VERSION ""

NS_ :

BS_ :

BU_: Charger BMS

BO_ 1031 BackEMF: 8 BMS
 SG_ BEMFd : 32|32@1- (1.0,0.0) [-2147483648.0|2147483647.0] "" Charger
 SG_ BEMFq : 0|32@1- (1.0,0.0) [-2147483648.0|2147483647.0] "" Charger
BO_ 57 BIM1BootloaderAddress: 2 BMS
 SG_ BIM1BootloaderAddress : 0|16@1- (1.0,0.0) [-32768.0|32767.0] "" Charger
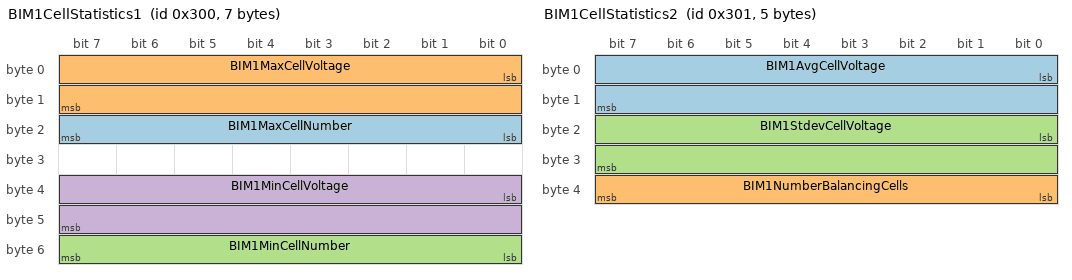
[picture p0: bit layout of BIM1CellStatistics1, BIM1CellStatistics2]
BO_ 768 BIM1CellStatistics1: 7 BMS
 SG_ BIM1MaxCellNumber : 16|8@1- (1.0,0.0) [-128.0|127.0] "" Charger
 SG_ BIM1MaxCellVoltage : 0|16@1- (1.0,0.0) [-32768.0|32767.0] "" Charger
 SG_ BIM1MinCellNumber : 48|8@1- (1.0,0.0) [-128.0|127.0] "" Charger
 SG_ BIM1MinCellVoltage : 32|16@1- (1.0,0.0) [-32768.0|32767.0] "" Charger
BO_ 769 BIM1CellStatistics2: 5 BMS
 SG_ BIM1AvgCellVoltage : 0|16@1- (1.0,0.0) [-32768.0|32767.0] "" Charger
 SG_ BIM1NumberBalancingCells : 32|8@1- (1.0,0.0) [-128.0|127.0] "" Charger
 SG_ BIM1StdevCellVoltage : 16|16@1- (1.0,0.0) [-32768.0|32767.0] "" Charger
BO_ 176 BIM1Command: 8 BMS
 SG_ BIM1CommandCode : 32|32@1- (1.0,0.0) [-2147483648.0|2147483647.0] "" Charger
 SG_ BIM1CommandValue : 0|32@1- (1.0,0.0) [-2147483648.0|2147483647.0] "" Charger
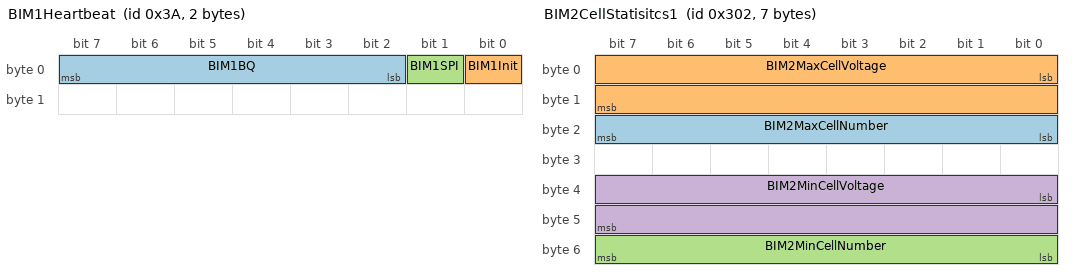
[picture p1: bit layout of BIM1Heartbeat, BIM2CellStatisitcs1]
BO_ 58 BIM1Heartbeat: 2 BMS
 SG_ BIM1BQ : 2|6@1- (1.0,0.0) [-32.0|31.0] "" Charger
 SG_ BIM1Init : 0|1@1- (1.0,0.0) [-1.0|0.0] "" Charger
 SG_ BIM1SPI : 1|1@1- (1.0,0.0) [-1.0|0.0] "" Charger
BO_ 59 BIM2BootloaderAddress: 2 BMS
 SG_ BIM2BootloaderAddres : 0|16@1- (1.0,0.0) [-32768.0|32767.0] "" Charger
BO_ 770 BIM2CellStatisitcs1: 7 BMS
 SG_ BIM2MaxCellNumber : 16|8@1- (1.0,0.0) [-128.0|127.0] "" Charger
 SG_ BIM2MaxCellVoltage : 0|16@1- (1.0,0.0) [-32768.0|32767.0] "" Charger
 SG_ BIM2MinCellNumber : 48|8@1- (1.0,0.0) [-128.0|127.0] "" Charger
 SG_ BIM2MinCellVoltage : 32|16@1- (1.0,0.0) [-32768.0|32767.0] "" Charger
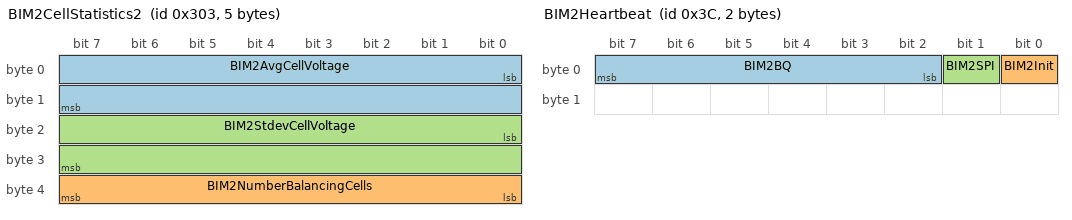
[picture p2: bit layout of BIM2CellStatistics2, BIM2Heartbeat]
BO_ 771 BIM2CellStatistics2: 5 BMS
 SG_ BIM2AvgCellVoltage : 0|16@1- (1.0,0.0) [-32768.0|32767.0] "" Charger
 SG_ BIM2NumberBalancingCells : 32|8@1- (1.0,0.0) [-128.0|127.0] "" Charger
 SG_ BIM2StdevCellVoltage : 16|16@1- (1.0,0.0) [-32768.0|32767.0] "" Charger
BO_ 177 BIM2Command: 8 BMS
 SG_ BIM2CommandCode : 32|32@1- (1.0,0.0) [-2147483648.0|2147483647.0] "" Charger
 SG_ BIM2CommandValue : 0|32@1- (1.0,0.0) [-2147483648.0|2147483647.0] "" Charger
BO_ 60 BIM2Heartbeat: 2 BMS
 SG_ BIM2BQ : 2|6@1- (1.0,0.0) [-32.0|31.0] "" Charger
 SG_ BIM2Init : 0|1@1- (1.0,0.0) [-1.0|0.0] "" Charger
 SG_ BIM2SPI : 1|1@1- (1.0,0.0) [-1.0|0.0] "" Charger
BO_ 61 BIM3BootloaderAddress: 2 BMS
 SG_ BIM3BootloaderAddress : 0|16@1- (1.0,0.0) [-32768.0|32767.0] "" Charger
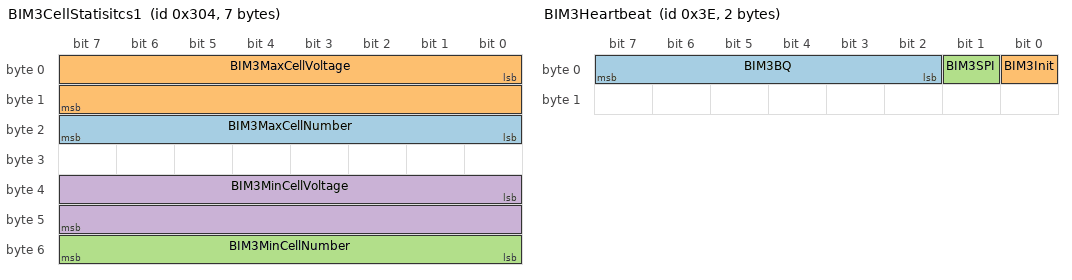
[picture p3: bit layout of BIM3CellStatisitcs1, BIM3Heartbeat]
BO_ 772 BIM3CellStatisitcs1: 7 BMS
 SG_ BIM3MaxCellNumber : 16|8@1- (1.0,0.0) [-128.0|127.0] "" Charger
 SG_ BIM3MaxCellVoltage : 0|16@1- (1.0,0.0) [-32768.0|32767.0] "" Charger
 SG_ BIM3MinCellNumber : 48|8@1- (1.0,0.0) [-128.0|127.0] "" Charger
 SG_ BIM3MinCellVoltage : 32|16@1- (1.0,0.0) [-32768.0|32767.0] "" Charger
BO_ 773 BIM3CellStatistics2: 5 BMS
 SG_ BIM3AvgCellVoltage : 0|16@1- (1.0,0.0) [-32768.0|32767.0] "" Charger
 SG_ BIM3NumberBalancingCells : 32|8@1- (1.0,0.0) [-128.0|127.0] "" Charger
 SG_ BIM3StdevCellVoltage : 16|16@1- (1.0,0.0) [-32768.0|32767.0] "" Charger
BO_ 178 BIM3Command: 8 BMS
 SG_ BIM3CommandCode : 32|32@1- (1.0,0.0) [-2147483648.0|2147483647.0] "" Charger
 SG_ BIM3CommandValue : 0|32@1- (1.0,0.0) [-2147483648.0|2147483647.0] "" Charger
BO_ 62 BIM3Heartbeat: 2 BMS
 SG_ BIM3BQ : 2|6@1- (1.0,0.0) [-32.0|31.0] "" Charger
 SG_ BIM3Init : 0|1@1- (1.0,0.0) [-1.0|0.0] "" Charger
 SG_ BIM3SPI : 1|1@1- (1.0,0.0) [-1.0|0.0] "" Charger
BO_ 63 BIM4BootloaderAddress: 2 BMS
 SG_ BIM4BootloaderAddres : 0|16@1- (1.0,0.0) [-32768.0|32767.0] "" Charger
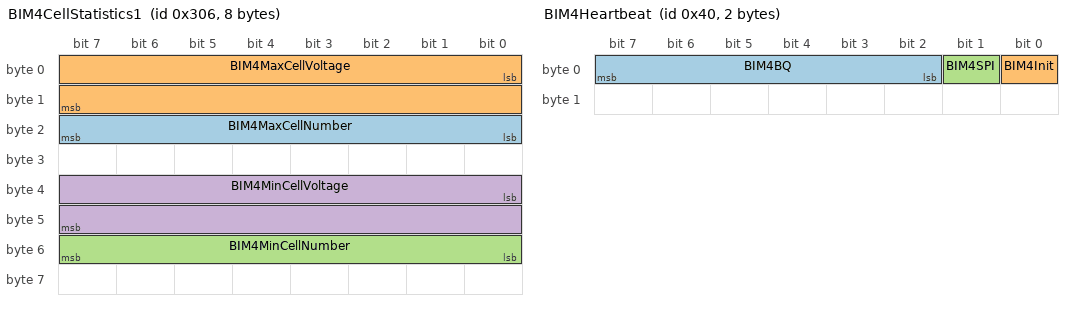
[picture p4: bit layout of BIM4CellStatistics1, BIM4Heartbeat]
BO_ 774 BIM4CellStatistics1: 8 BMS
 SG_ BIM4MaxCellNumber : 16|8@1- (1.0,0.0) [-128.0|127.0] "" Charger
 SG_ BIM4MaxCellVoltage : 0|16@1- (1.0,0.0) [-32768.0|32767.0] "" Charger
 SG_ BIM4MinCellNumber : 48|8@1- (1.0,0.0) [-128.0|127.0] "" Charger
 SG_ BIM4MinCellVoltage : 32|16@1- (1.0,0.0) [-32768.0|32767.0] "" Charger
BO_ 775 BIM4CellStatistics2: 5 BMS
 SG_ BIM4AvgCellVoltage : 0|16@1- (1.0,0.0) [-32768.0|32767.0] "" Charger
 SG_ BIM4NumberBalancingCells : 32|8@1- (1.0,0.0) [-128.0|127.0] "" Charger
 SG_ BIM4StdevCellVoltage : 16|16@1- (1.0,0.0) [-32768.0|32767.0] "" Charger
BO_ 179 BIM4Command: 8 BMS
 SG_ BIM4CommandCode : 32|32@1- (1.0,0.0) [-2147483648.0|2147483647.0] "" Charger
 SG_ BIM4CommandValue : 0|32@1- (1.0,0.0) [-2147483648.0|2147483647.0] "" Charger
BO_ 64 BIM4Heartbeat: 2 BMS
 SG_ BIM4BQ : 2|6@1- (1.0,0.0) [-32.0|31.0] "" Charger
 SG_ BIM4Init : 0|1@1- (1.0,0.0) [-1.0|0.0] "" Charger
 SG_ BIM4SPI : 1|1@1- (1.0,0.0) [-1.0|0.0] "" Charger
BO_ 1026 BusMeasurement: 8 BMS
 SG_ BusCurrent : 32|32@1- (1.0,0.0) [-2147483648.0|2147483647.0] "" Charger
 SG_ BusVoltage : 0|32@1- (1.0,0.0) [-2147483648.0|2147483647.0] "" Charger
BO_ 262 BusVoltage12V: 4 BMS
 SG_ BusVoltage12V : 0|32@1- (1.0,0.0) [-2147483648.0|2147483647.0] "" Charger
BO_ 170 CANcorderHeartbeat: 2 Charger
 SG_ CANcorderHeartbeat : 0|16@1- (1.0,0.0) [-32768.0|32767.0] "" BMS
BO_ 48 CANMirrorBootloaderAddress: 2 Charger
 SG_ CANMirrorBootloaderAddress : 0|16@1- (1.0,0.0) [-32768.0|32767.0] "" BMS
BO_ 50 CANMirrorCommand: 8 Charger
 SG_ CANMirrorCommandCode : 32|32@1- (1.0,0.0) [-2147483648.0|2147483647.0] "" BMS
 SG_ CANMirrorCommandValue : 0|32@1- (1.0,0.0) [-2147483648.0|2147483647.0] "" BMS
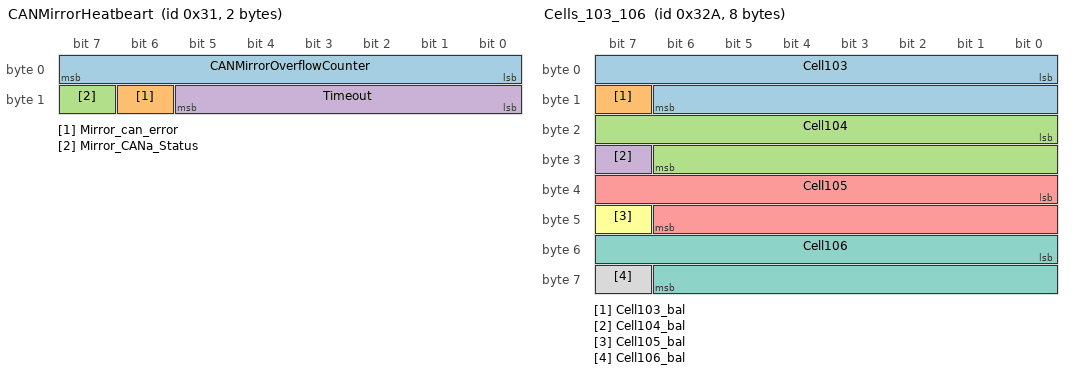
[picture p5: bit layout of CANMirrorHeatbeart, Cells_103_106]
BO_ 49 CANMirrorHeatbeart: 2 Charger
 SG_ CANMirrorOverflowCounter : 0|8@1- (1.0,0.0) [-128.0|127.0] "" BMS
 SG_ Mirror_can_error : 14|1@1- (1.0,0.0) [-1.0|0.0] "" BMS
 SG_ Mirror_CANa_Status : 15|1@1- (1.0,0.0) [-1.0|0.0] "" BMS
 SG_ Timeout : 8|6@1- (1.0,0.0) [-32.0|31.0] "" BMS
BO_ 810 Cells_103_106: 8 Charger
 SG_ Cell103 : 0|15@1- (1.0,0.0) [-16384.0|16383.0] "" BMS
 SG_ Cell103_bal : 15|1@1- (1.0,0.0) [-1.0|0.0] "" BMS
 SG_ Cell104 : 16|15@1- (1.0,0.0) [-16384.0|16383.0] "" BMS
 SG_ Cell104_bal : 31|1@1- (1.0,0.0) [-1.0|0.0] "" BMS
 SG_ Cell105 : 32|15@1- (1.0,0.0) [-16384.0|16383.0] "" BMS
 SG_ Cell105_bal : 47|1@1- (1.0,0.0) [-1.0|0.0] "" BMS
 SG_ Cell106 : 48|15@1- (1.0,0.0) [-16384.0|16383.0] "" BMS
 SG_ Cell106_bal : 63|1@1- (1.0,0.0) [-1.0|0.0] "" BMS
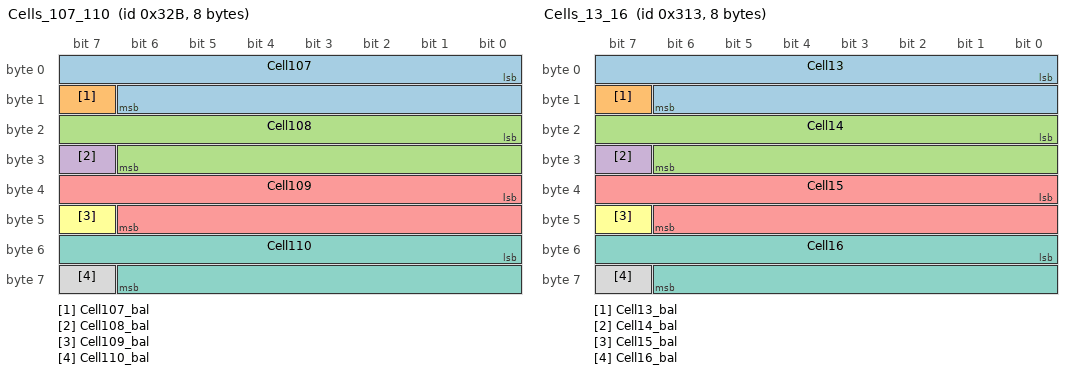
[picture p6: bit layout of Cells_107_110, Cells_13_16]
BO_ 811 Cells_107_110: 8 Charger
 SG_ Cell107 : 0|15@1- (1.0,0.0) [-16384.0|16383.0] "" BMS
 SG_ Cell107_bal : 15|1@1- (1.0,0.0) [-1.0|0.0] "" BMS
 SG_ Cell108 : 16|15@1- (1.0,0.0) [-16384.0|16383.0] "" BMS
 SG_ Cell108_bal : 31|1@1- (1.0,0.0) [-1.0|0.0] "" BMS
 SG_ Cell109 : 32|15@1- (1.0,0.0) [-16384.0|16383.0] "" BMS
 SG_ Cell109_bal : 47|1@1- (1.0,0.0) [-1.0|0.0] "" BMS
 SG_ Cell110 : 48|15@1- (1.0,0.0) [-16384.0|16383.0] "" BMS
 SG_ Cell110_bal : 63|1@1- (1.0,0.0) [-1.0|0.0] "" BMS
BO_ 787 Cells_13_16: 8 Charger
 SG_ Cell13 : 0|15@1- (1.0,0.0) [-16384.0|16383.0] "" BMS
 SG_ Cell13_bal : 15|1@1- (1.0,0.0) [-1.0|0.0] "" BMS
 SG_ Cell14 : 16|15@1- (1.0,0.0) [-16384.0|16383.0] "" BMS
 SG_ Cell14_bal : 31|1@1- (1.0,0.0) [-1.0|0.0] "" BMS
 SG_ Cell15 : 32|15@1- (1.0,0.0) [-16384.0|16383.0] "" BMS
 SG_ Cell15_bal : 47|1@1- (1.0,0.0) [-1.0|0.0] "" BMS
 SG_ Cell16 : 48|15@1- (1.0,0.0) [-16384.0|16383.0] "" BMS
 SG_ Cell16_bal : 63|1@1- (1.0,0.0) [-1.0|0.0] "" BMS
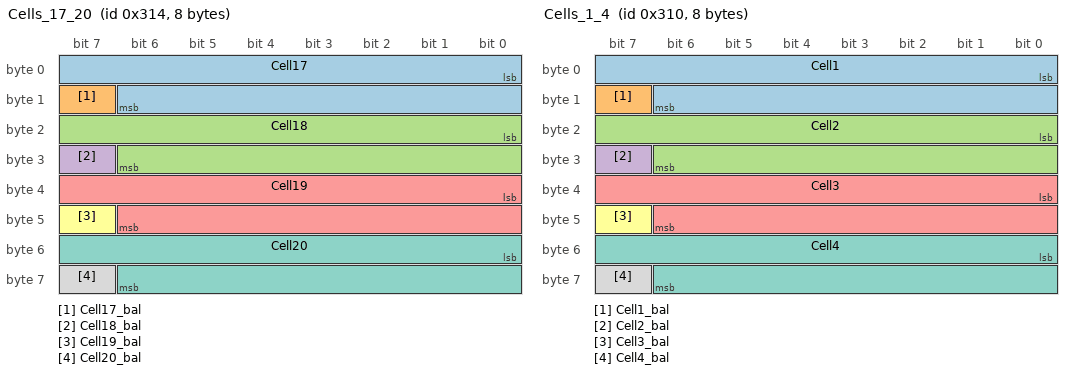
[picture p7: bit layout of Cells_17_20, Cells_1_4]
BO_ 788 Cells_17_20: 8 Charger
 SG_ Cell17 : 0|15@1- (1.0,0.0) [-16384.0|16383.0] "" BMS
 SG_ Cell17_bal : 15|1@1- (1.0,0.0) [-1.0|0.0] "" BMS
 SG_ Cell18 : 16|15@1- (1.0,0.0) [-16384.0|16383.0] "" BMS
 SG_ Cell18_bal : 31|1@1- (1.0,0.0) [-1.0|0.0] "" BMS
 SG_ Cell19 : 32|15@1- (1.0,0.0) [-16384.0|16383.0] "" BMS
 SG_ Cell19_bal : 47|1@1- (1.0,0.0) [-1.0|0.0] "" BMS
 SG_ Cell20 : 48|15@1- (1.0,0.0) [-16384.0|16383.0] "" BMS
 SG_ Cell20_bal : 63|1@1- (1.0,0.0) [-1.0|0.0] "" BMS
BO_ 784 Cells_1_4: 8 Charger
 SG_ Cell1 : 0|15@1- (1.0,0.0) [-16384.0|16383.0] "" BMS
 SG_ Cell1_bal : 15|1@1- (1.0,0.0) [-1.0|0.0] "" BMS
 SG_ Cell2 : 16|15@1- (1.0,0.0) [-16384.0|16383.0] "" BMS
 SG_ Cell2_bal : 31|1@1- (1.0,0.0) [-1.0|0.0] "" BMS
 SG_ Cell3 : 32|15@1- (1.0,0.0) [-16384.0|16383.0] "" BMS
 SG_ Cell3_bal : 47|1@1- (1.0,0.0) [-1.0|0.0] "" BMS
 SG_ Cell4 : 48|15@1- (1.0,0.0) [-16384.0|16383.0] "" BMS
 SG_ Cell4_bal : 63|1@1- (1.0,0.0) [-1.0|0.0] "" BMS
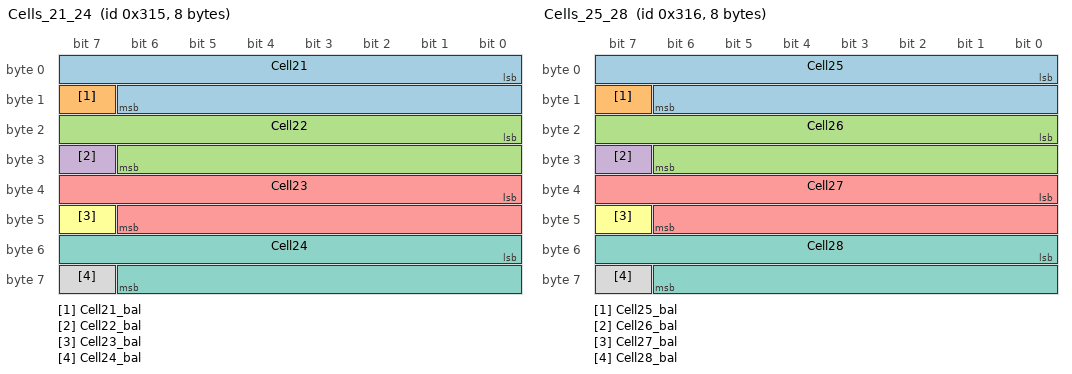
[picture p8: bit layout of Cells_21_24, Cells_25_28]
BO_ 789 Cells_21_24: 8 Charger
 SG_ Cell21 : 0|15@1- (1.0,0.0) [-16384.0|16383.0] "" BMS
 SG_ Cell21_bal : 15|1@1- (1.0,0.0) [-1.0|0.0] "" BMS
 SG_ Cell22 : 16|15@1- (1.0,0.0) [-16384.0|16383.0] "" BMS
 SG_ Cell22_bal : 31|1@1- (1.0,0.0) [-1.0|0.0] "" BMS
 SG_ Cell23 : 32|15@1- (1.0,0.0) [-16384.0|16383.0] "" BMS
 SG_ Cell23_bal : 47|1@1- (1.0,0.0) [-1.0|0.0] "" BMS
 SG_ Cell24 : 48|15@1- (1.0,0.0) [-16384.0|16383.0] "" BMS
 SG_ Cell24_bal : 63|1@1- (1.0,0.0) [-1.0|0.0] "" BMS
BO_ 790 Cells_25_28: 8 Charger
 SG_ Cell25 : 0|15@1- (1.0,0.0) [-16384.0|16383.0] "" BMS
 SG_ Cell25_bal : 15|1@1- (1.0,0.0) [-1.0|0.0] "" BMS
 SG_ Cell26 : 16|15@1- (1.0,0.0) [-16384.0|16383.0] "" BMS
 SG_ Cell26_bal : 31|1@1- (1.0,0.0) [-1.0|0.0] "" BMS
 SG_ Cell27 : 32|15@1- (1.0,0.0) [-16384.0|16383.0] "" BMS
 SG_ Cell27_bal : 47|1@1- (1.0,0.0) [-1.0|0.0] "" BMS
 SG_ Cell28 : 48|15@1- (1.0,0.0) [-16384.0|16383.0] "" BMS
 SG_ Cell28_bal : 63|1@1- (1.0,0.0) [-1.0|0.0] "" BMS
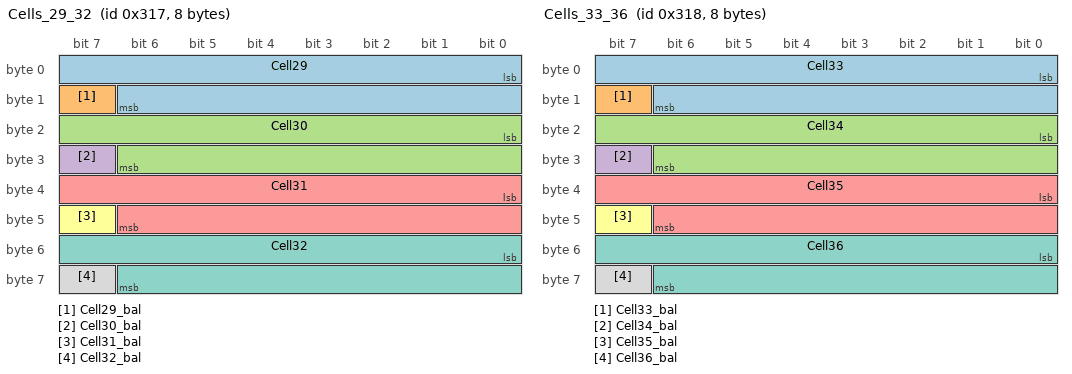
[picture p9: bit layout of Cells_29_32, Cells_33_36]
BO_ 791 Cells_29_32: 8 Charger
 SG_ Cell29 : 0|15@1- (1.0,0.0) [-16384.0|16383.0] "" BMS
 SG_ Cell29_bal : 15|1@1- (1.0,0.0) [-1.0|0.0] "" BMS
 SG_ Cell30 : 16|15@1- (1.0,0.0) [-16384.0|16383.0] "" BMS
 SG_ Cell30_bal : 31|1@1- (1.0,0.0) [-1.0|0.0] "" BMS
 SG_ Cell31 : 32|15@1- (1.0,0.0) [-16384.0|16383.0] "" BMS
 SG_ Cell31_bal : 47|1@1- (1.0,0.0) [-1.0|0.0] "" BMS
 SG_ Cell32 : 48|15@1- (1.0,0.0) [-16384.0|16383.0] "" BMS
 SG_ Cell32_bal : 63|1@1- (1.0,0.0) [-1.0|0.0] "" BMS
BO_ 792 Cells_33_36: 8 Charger
 SG_ Cell33 : 0|15@1- (1.0,0.0) [-16384.0|16383.0] "" BMS
 SG_ Cell33_bal : 15|1@1- (1.0,0.0) [-1.0|0.0] "" BMS
 SG_ Cell34 : 16|15@1- (1.0,0.0) [-16384.0|16383.0] "" BMS
 SG_ Cell34_bal : 31|1@1- (1.0,0.0) [-1.0|0.0] "" BMS
 SG_ Cell35 : 32|15@1- (1.0,0.0) [-16384.0|16383.0] "" BMS
 SG_ Cell35_bal : 47|1@1- (1.0,0.0) [-1.0|0.0] "" BMS
 SG_ Cell36 : 48|15@1- (1.0,0.0) [-16384.0|16383.0] "" BMS
 SG_ Cell36_bal : 63|1@1- (1.0,0.0) [-1.0|0.0] "" BMS
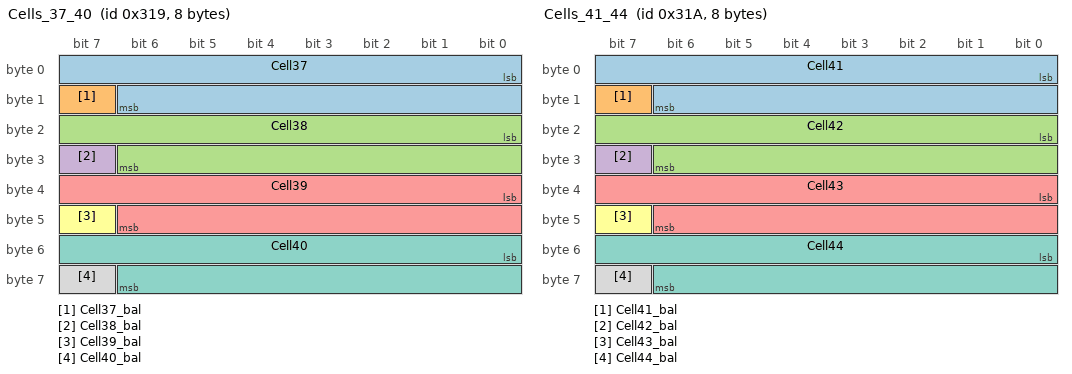
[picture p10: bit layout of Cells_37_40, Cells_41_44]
BO_ 793 Cells_37_40: 8 Charger
 SG_ Cell37 : 0|15@1- (1.0,0.0) [-16384.0|16383.0] "" BMS
 SG_ Cell37_bal : 15|1@1- (1.0,0.0) [-1.0|0.0] "" BMS
 SG_ Cell38 : 16|15@1- (1.0,0.0) [-16384.0|16383.0] "" BMS
 SG_ Cell38_bal : 31|1@1- (1.0,0.0) [-1.0|0.0] "" BMS
 SG_ Cell39 : 32|15@1- (1.0,0.0) [-16384.0|16383.0] "" BMS
 SG_ Cell39_bal : 47|1@1- (1.0,0.0) [-1.0|0.0] "" BMS
 SG_ Cell40 : 48|15@1- (1.0,0.0) [-16384.0|16383.0] "" BMS
 SG_ Cell40_bal : 63|1@1- (1.0,0.0) [-1.0|0.0] "" BMS
BO_ 794 Cells_41_44: 8 Charger
 SG_ Cell41 : 0|15@1- (1.0,0.0) [-16384.0|16383.0] "" BMS
 SG_ Cell41_bal : 15|1@1- (1.0,0.0) [-1.0|0.0] "" BMS
 SG_ Cell42 : 16|15@1- (1.0,0.0) [-16384.0|16383.0] "" BMS
 SG_ Cell42_bal : 31|1@1- (1.0,0.0) [-1.0|0.0] "" BMS
 SG_ Cell43 : 32|15@1- (1.0,0.0) [-16384.0|16383.0] "" BMS
 SG_ Cell43_bal : 47|1@1- (1.0,0.0) [-1.0|0.0] "" BMS
 SG_ Cell44 : 48|15@1- (1.0,0.0) [-16384.0|16383.0] "" BMS
 SG_ Cell44_bal : 63|1@1- (1.0,0.0) [-1.0|0.0] "" BMS
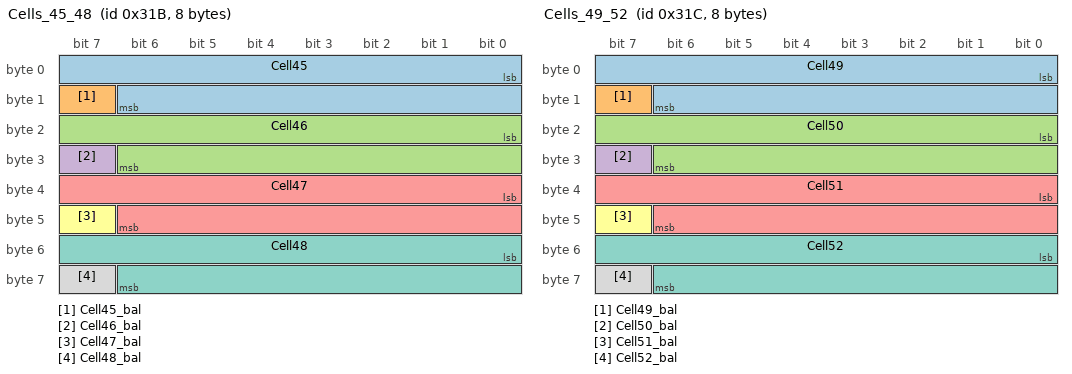
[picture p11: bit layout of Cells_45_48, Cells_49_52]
BO_ 795 Cells_45_48: 8 Charger
 SG_ Cell45 : 0|15@1- (1.0,0.0) [-16384.0|16383.0] "" BMS
 SG_ Cell45_bal : 15|1@1- (1.0,0.0) [-1.0|0.0] "" BMS
 SG_ Cell46 : 16|15@1- (1.0,0.0) [-16384.0|16383.0] "" BMS
 SG_ Cell46_bal : 31|1@1- (1.0,0.0) [-1.0|0.0] "" BMS
 SG_ Cell47 : 32|15@1- (1.0,0.0) [-16384.0|16383.0] "" BMS
 SG_ Cell47_bal : 47|1@1- (1.0,0.0) [-1.0|0.0] "" BMS
 SG_ Cell48 : 48|15@1- (1.0,0.0) [-16384.0|16383.0] "" BMS
 SG_ Cell48_bal : 63|1@1- (1.0,0.0) [-1.0|0.0] "" BMS
BO_ 796 Cells_49_52: 8 Charger
 SG_ Cell49 : 0|15@1- (1.0,0.0) [-16384.0|16383.0] "" BMS
 SG_ Cell49_bal : 15|1@1- (1.0,0.0) [-1.0|0.0] "" BMS
 SG_ Cell50 : 16|15@1- (1.0,0.0) [-16384.0|16383.0] "" BMS
 SG_ Cell50_bal : 31|1@1- (1.0,0.0) [-1.0|0.0] "" BMS
 SG_ Cell51 : 32|15@1- (1.0,0.0) [-16384.0|16383.0] "" BMS
 SG_ Cell51_bal : 47|1@1- (1.0,0.0) [-1.0|0.0] "" BMS
 SG_ Cell52 : 48|15@1- (1.0,0.0) [-16384.0|16383.0] "" BMS
 SG_ Cell52_bal : 63|1@1- (1.0,0.0) [-1.0|0.0] "" BMS
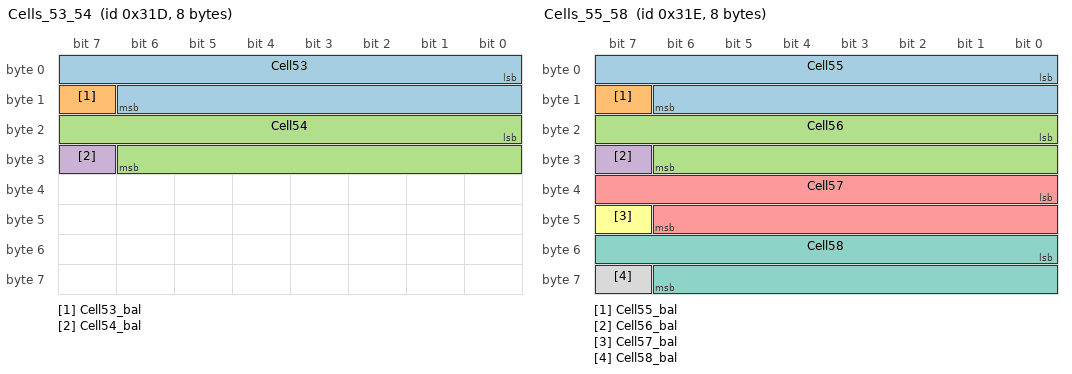
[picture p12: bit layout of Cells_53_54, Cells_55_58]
BO_ 797 Cells_53_54: 8 Charger
 SG_ Cell53 : 0|15@1- (1.0,0.0) [-16384.0|16383.0] "" BMS
 SG_ Cell53_bal : 15|1@1- (1.0,0.0) [-1.0|0.0] "" BMS
 SG_ Cell54 : 16|15@1- (1.0,0.0) [-16384.0|16383.0] "" BMS
 SG_ Cell54_bal : 31|1@1- (1.0,0.0) [-1.0|0.0] "" BMS
BO_ 798 Cells_55_58: 8 Charger
 SG_ Cell55 : 0|15@1- (1.0,0.0) [-16384.0|16383.0] "" BMS
 SG_ Cell55_bal : 15|1@1- (1.0,0.0) [-1.0|0.0] "" BMS
 SG_ Cell56 : 16|15@1- (1.0,0.0) [-16384.0|16383.0] "" BMS
 SG_ Cell56_bal : 31|1@1- (1.0,0.0) [-1.0|0.0] "" BMS
 SG_ Cell57 : 32|15@1- (1.0,0.0) [-16384.0|16383.0] "" BMS
 SG_ Cell57_bal : 47|1@1- (1.0,0.0) [-1.0|0.0] "" BMS
 SG_ Cell58 : 48|15@1- (1.0,0.0) [-16384.0|16383.0] "" BMS
 SG_ Cell58_bal : 63|1@1- (1.0,0.0) [-1.0|0.0] "" BMS
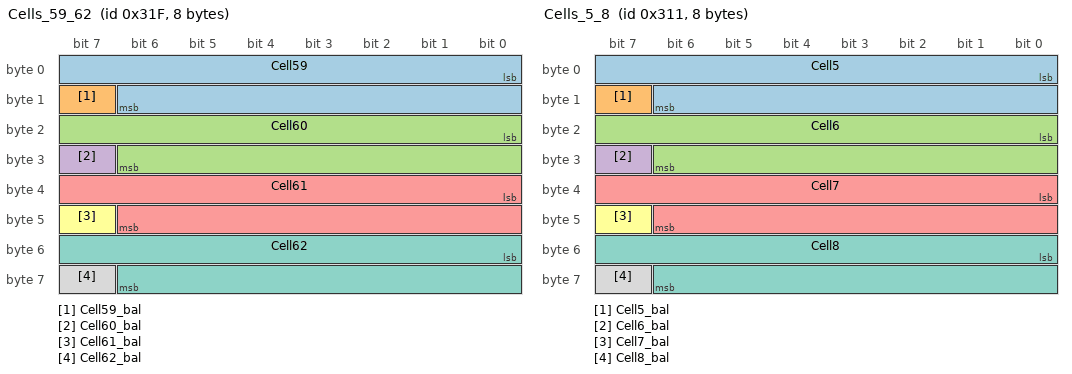
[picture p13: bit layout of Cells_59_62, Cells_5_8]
BO_ 799 Cells_59_62: 8 Charger
 SG_ Cell59 : 0|15@1- (1.0,0.0) [-16384.0|16383.0] "" BMS
 SG_ Cell59_bal : 15|1@1- (1.0,0.0) [-1.0|0.0] "" BMS
 SG_ Cell60 : 16|15@1- (1.0,0.0) [-16384.0|16383.0] "" BMS
 SG_ Cell60_bal : 31|1@1- (1.0,0.0) [-1.0|0.0] "" BMS
 SG_ Cell61 : 32|15@1- (1.0,0.0) [-16384.0|16383.0] "" BMS
 SG_ Cell61_bal : 47|1@1- (1.0,0.0) [-1.0|0.0] "" BMS
 SG_ Cell62 : 48|15@1- (1.0,0.0) [-16384.0|16383.0] "" BMS
 SG_ Cell62_bal : 63|1@1- (1.0,0.0) [-1.0|0.0] "" BMS
BO_ 785 Cells_5_8: 8 Charger
 SG_ Cell5 : 0|15@1- (1.0,0.0) [-16384.0|16383.0] "" BMS
 SG_ Cell5_bal : 15|1@1- (1.0,0.0) [-1.0|0.0] "" BMS
 SG_ Cell6 : 16|15@1- (1.0,0.0) [-16384.0|16383.0] "" BMS
 SG_ Cell6_bal : 31|1@1- (1.0,0.0) [-1.0|0.0] "" BMS
 SG_ Cell7 : 32|15@1- (1.0,0.0) [-16384.0|16383.0] "" BMS
 SG_ Cell7_bal : 47|1@1- (1.0,0.0) [-1.0|0.0] "" BMS
 SG_ Cell8 : 48|15@1- (1.0,0.0) [-16384.0|16383.0] "" BMS
 SG_ Cell8_bal : 63|1@1- (1.0,0.0) [-1.0|0.0] "" BMS
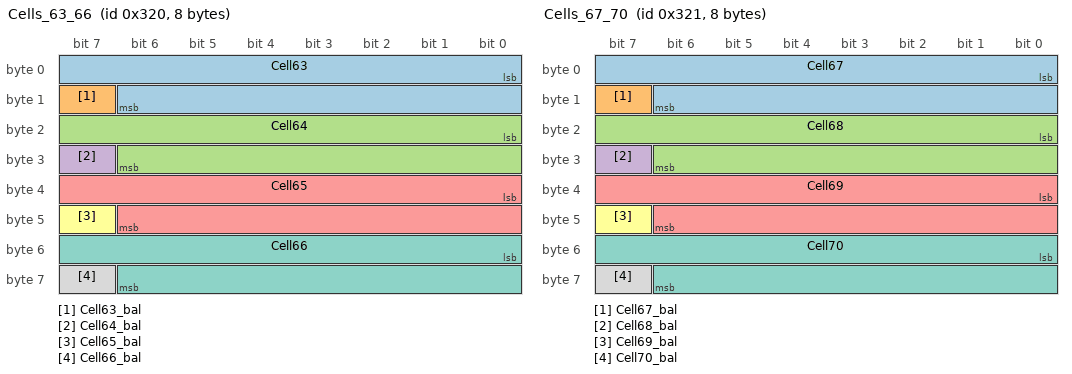
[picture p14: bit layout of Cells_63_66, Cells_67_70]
BO_ 800 Cells_63_66: 8 Charger
 SG_ Cell63 : 0|15@1- (1.0,0.0) [-16384.0|16383.0] "" BMS
 SG_ Cell63_bal : 15|1@1- (1.0,0.0) [-1.0|0.0] "" BMS
 SG_ Cell64 : 16|15@1- (1.0,0.0) [-16384.0|16383.0] "" BMS
 SG_ Cell64_bal : 31|1@1- (1.0,0.0) [-1.0|0.0] "" BMS
 SG_ Cell65 : 32|15@1- (1.0,0.0) [-16384.0|16383.0] "" BMS
 SG_ Cell65_bal : 47|1@1- (1.0,0.0) [-1.0|0.0] "" BMS
 SG_ Cell66 : 48|15@1- (1.0,0.0) [-16384.0|16383.0] "" BMS
 SG_ Cell66_bal : 63|1@1- (1.0,0.0) [-1.0|0.0] "" BMS
BO_ 801 Cells_67_70: 8 Charger
 SG_ Cell67 : 0|15@1- (1.0,0.0) [-16384.0|16383.0] "" BMS
 SG_ Cell67_bal : 15|1@1- (1.0,0.0) [-1.0|0.0] "" BMS
 SG_ Cell68 : 16|15@1- (1.0,0.0) [-16384.0|16383.0] "" BMS
 SG_ Cell68_bal : 31|1@1- (1.0,0.0) [-1.0|0.0] "" BMS
 SG_ Cell69 : 32|15@1- (1.0,0.0) [-16384.0|16383.0] "" BMS
 SG_ Cell69_bal : 47|1@1- (1.0,0.0) [-1.0|0.0] "" BMS
 SG_ Cell70 : 48|15@1- (1.0,0.0) [-16384.0|16383.0] "" BMS
 SG_ Cell70_bal : 63|1@1- (1.0,0.0) [-1.0|0.0] "" BMS
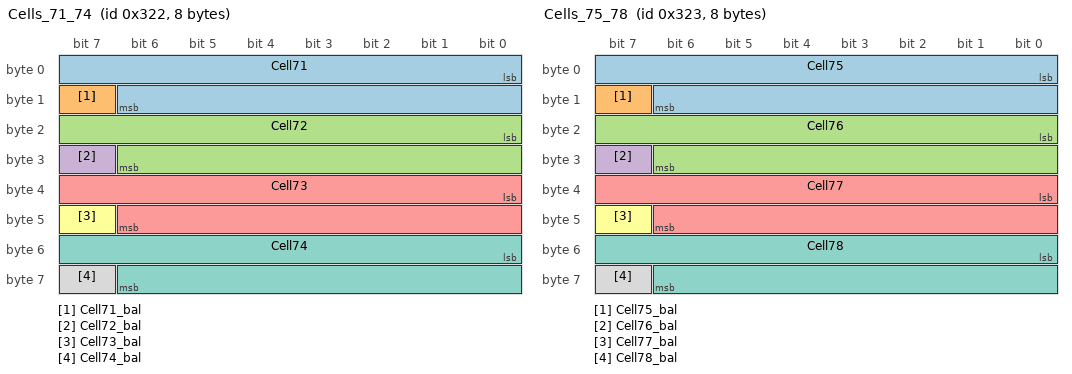
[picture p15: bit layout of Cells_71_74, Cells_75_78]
BO_ 802 Cells_71_74: 8 Charger
 SG_ Cell71 : 0|15@1- (1.0,0.0) [-16384.0|16383.0] "" BMS
 SG_ Cell71_bal : 15|1@1- (1.0,0.0) [-1.0|0.0] "" BMS
 SG_ Cell72 : 16|15@1- (1.0,0.0) [-16384.0|16383.0] "" BMS
 SG_ Cell72_bal : 31|1@1- (1.0,0.0) [-1.0|0.0] "" BMS
 SG_ Cell73 : 32|15@1- (1.0,0.0) [-16384.0|16383.0] "" BMS
 SG_ Cell73_bal : 47|1@1- (1.0,0.0) [-1.0|0.0] "" BMS
 SG_ Cell74 : 48|15@1- (1.0,0.0) [-16384.0|16383.0] "" BMS
 SG_ Cell74_bal : 63|1@1- (1.0,0.0) [-1.0|0.0] "" BMS
BO_ 803 Cells_75_78: 8 Charger
 SG_ Cell75 : 0|15@1- (1.0,0.0) [-16384.0|16383.0] "" BMS
 SG_ Cell75_bal : 15|1@1- (1.0,0.0) [-1.0|0.0] "" BMS
 SG_ Cell76 : 16|15@1- (1.0,0.0) [-16384.0|16383.0] "" BMS
 SG_ Cell76_bal : 31|1@1- (1.0,0.0) [-1.0|0.0] "" BMS
 SG_ Cell77 : 32|15@1- (1.0,0.0) [-16384.0|16383.0] "" BMS
 SG_ Cell77_bal : 47|1@1- (1.0,0.0) [-1.0|0.0] "" BMS
 SG_ Cell78 : 48|15@1- (1.0,0.0) [-16384.0|16383.0] "" BMS
 SG_ Cell78_bal : 63|1@1- (1.0,0.0) [-1.0|0.0] "" BMS
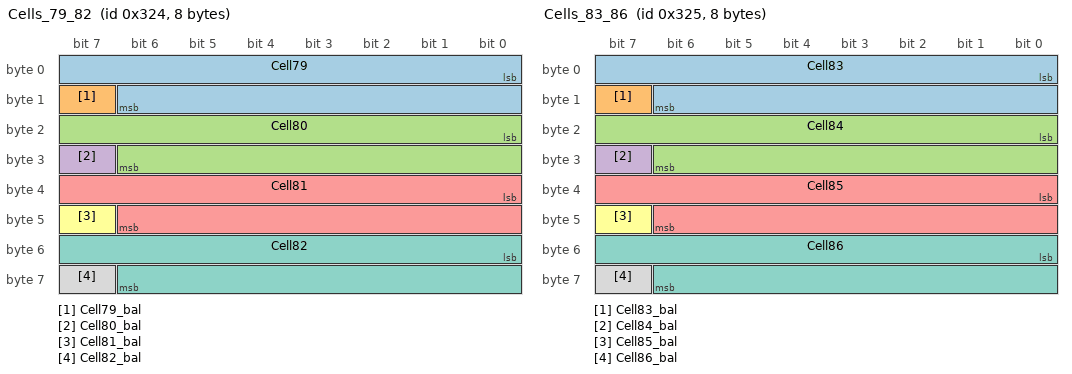
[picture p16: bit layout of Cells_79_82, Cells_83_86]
BO_ 804 Cells_79_82: 8 Charger
 SG_ Cell79 : 0|15@1- (1.0,0.0) [-16384.0|16383.0] "" BMS
 SG_ Cell79_bal : 15|1@1- (1.0,0.0) [-1.0|0.0] "" BMS
 SG_ Cell80 : 16|15@1- (1.0,0.0) [-16384.0|16383.0] "" BMS
 SG_ Cell80_bal : 31|1@1- (1.0,0.0) [-1.0|0.0] "" BMS
 SG_ Cell81 : 32|15@1- (1.0,0.0) [-16384.0|16383.0] "" BMS
 SG_ Cell81_bal : 47|1@1- (1.0,0.0) [-1.0|0.0] "" BMS
 SG_ Cell82 : 48|15@1- (1.0,0.0) [-16384.0|16383.0] "" BMS
 SG_ Cell82_bal : 63|1@1- (1.0,0.0) [-1.0|0.0] "" BMS
BO_ 805 Cells_83_86: 8 Charger
 SG_ Cell83 : 0|15@1- (1.0,0.0) [-16384.0|16383.0] "" BMS
 SG_ Cell83_bal : 15|1@1- (1.0,0.0) [-1.0|0.0] "" BMS
 SG_ Cell84 : 16|15@1- (1.0,0.0) [-16384.0|16383.0] "" BMS
 SG_ Cell84_bal : 31|1@1- (1.0,0.0) [-1.0|0.0] "" BMS
 SG_ Cell85 : 32|15@1- (1.0,0.0) [-16384.0|16383.0] "" BMS
 SG_ Cell85_bal : 47|1@1- (1.0,0.0) [-1.0|0.0] "" BMS
 SG_ Cell86 : 48|15@1- (1.0,0.0) [-16384.0|16383.0] "" BMS
 SG_ Cell86_bal : 63|1@1- (1.0,0.0) [-1.0|0.0] "" BMS
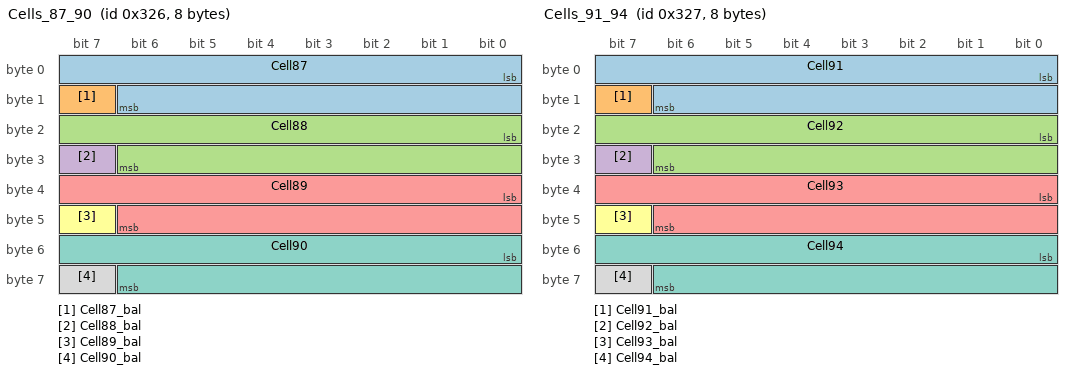
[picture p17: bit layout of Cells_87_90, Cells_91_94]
BO_ 806 Cells_87_90: 8 Charger
 SG_ Cell87 : 0|15@1- (1.0,0.0) [-16384.0|16383.0] "" BMS
 SG_ Cell87_bal : 15|1@1- (1.0,0.0) [-1.0|0.0] "" BMS
 SG_ Cell88 : 16|15@1- (1.0,0.0) [-16384.0|16383.0] "" BMS
 SG_ Cell88_bal : 31|1@1- (1.0,0.0) [-1.0|0.0] "" BMS
 SG_ Cell89 : 32|15@1- (1.0,0.0) [-16384.0|16383.0] "" BMS
 SG_ Cell89_bal : 47|1@1- (1.0,0.0) [-1.0|0.0] "" BMS
 SG_ Cell90 : 48|15@1- (1.0,0.0) [-16384.0|16383.0] "" BMS
 SG_ Cell90_bal : 63|1@1- (1.0,0.0) [-1.0|0.0] "" BMS
BO_ 807 Cells_91_94: 8 Charger
 SG_ Cell91 : 0|15@1- (1.0,0.0) [-16384.0|16383.0] "" BMS
 SG_ Cell91_bal : 15|1@1- (1.0,0.0) [-1.0|0.0] "" BMS
 SG_ Cell92 : 16|15@1- (1.0,0.0) [-16384.0|16383.0] "" BMS
 SG_ Cell92_bal : 31|1@1- (1.0,0.0) [-1.0|0.0] "" BMS
 SG_ Cell93 : 32|15@1- (1.0,0.0) [-16384.0|16383.0] "" BMS
 SG_ Cell93_bal : 47|1@1- (1.0,0.0) [-1.0|0.0] "" BMS
 SG_ Cell94 : 48|15@1- (1.0,0.0) [-16384.0|16383.0] "" BMS
 SG_ Cell94_bal : 63|1@1- (1.0,0.0) [-1.0|0.0] "" BMS
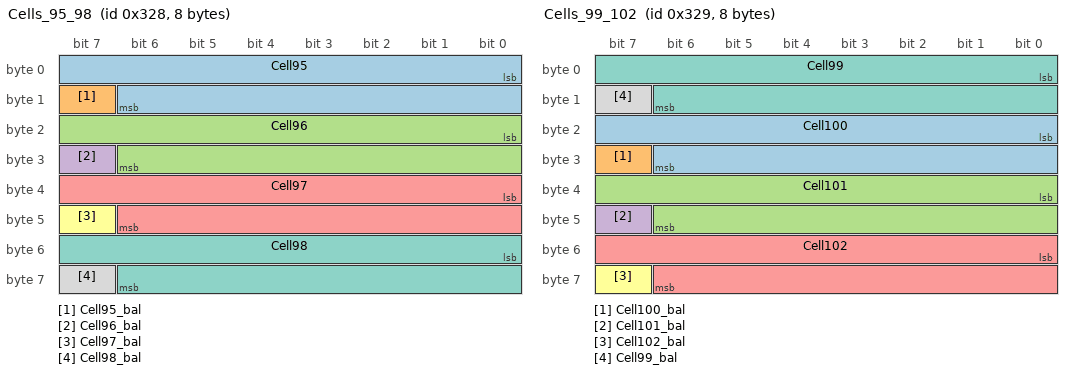
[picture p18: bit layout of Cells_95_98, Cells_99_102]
BO_ 808 Cells_95_98: 8 Charger
 SG_ Cell95 : 0|15@1- (1.0,0.0) [-16384.0|16383.0] "" BMS
 SG_ Cell95_bal : 15|1@1- (1.0,0.0) [-1.0|0.0] "" BMS
 SG_ Cell96 : 16|15@1- (1.0,0.0) [-16384.0|16383.0] "" BMS
 SG_ Cell96_bal : 31|1@1- (1.0,0.0) [-1.0|0.0] "" BMS
 SG_ Cell97 : 32|15@1- (1.0,0.0) [-16384.0|16383.0] "" BMS
 SG_ Cell97_bal : 47|1@1- (1.0,0.0) [-1.0|0.0] "" BMS
 SG_ Cell98 : 48|15@1- (1.0,0.0) [-16384.0|16383.0] "" BMS
 SG_ Cell98_bal : 63|1@1- (1.0,0.0) [-1.0|0.0] "" BMS
BO_ 809 Cells_99_102: 8 Charger
 SG_ Cell100 : 16|15@1- (1.0,0.0) [-16384.0|16383.0] "" BMS
 SG_ Cell100_bal : 31|1@1- (1.0,0.0) [-1.0|0.0] "" BMS
 SG_ Cell101 : 32|15@1- (1.0,0.0) [-16384.0|16383.0] "" BMS
 SG_ Cell101_bal : 47|1@1- (1.0,0.0) [-1.0|0.0] "" BMS
 SG_ Cell102 : 48|15@1- (1.0,0.0) [-16384.0|16383.0] "" BMS
 SG_ Cell102_bal : 63|1@1- (1.0,0.0) [-1.0|0.0] "" BMS
 SG_ Cell99 : 0|15@1- (1.0,0.0) [-16384.0|16383.0] "" BMS
 SG_ Cell99_bal : 15|1@1- (1.0,0.0) [-1.0|0.0] "" BMS
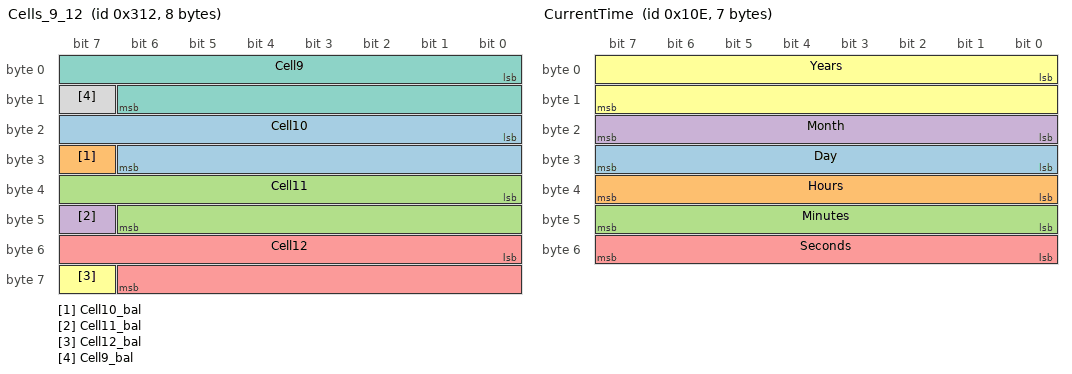
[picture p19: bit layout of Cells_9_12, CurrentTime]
BO_ 786 Cells_9_12: 8 Charger
 SG_ Cell10 : 16|15@1- (1.0,0.0) [-16384.0|16383.0] "" BMS
 SG_ Cell10_bal : 31|1@1- (1.0,0.0) [-1.0|0.0] "" BMS
 SG_ Cell11 : 32|15@1- (1.0,0.0) [-16384.0|16383.0] "" BMS
 SG_ Cell11_bal : 47|1@1- (1.0,0.0) [-1.0|0.0] "" BMS
 SG_ Cell12 : 48|15@1- (1.0,0.0) [-16384.0|16383.0] "" BMS
 SG_ Cell12_bal : 63|1@1- (1.0,0.0) [-1.0|0.0] "" BMS
 SG_ Cell9 : 0|15@1- (1.0,0.0) [-16384.0|16383.0] "" BMS
 SG_ Cell9_bal : 15|1@1- (1.0,0.0) [-1.0|0.0] "" BMS
BO_ 270 CurrentTime: 7 Charger
 SG_ Day : 24|8@1- (1.0,0.0) [-128.0|127.0] "" BMS
 SG_ Hours : 32|8@1- (1.0,0.0) [-128.0|127.0] "" BMS
 SG_ Minutes : 40|8@1- (1.0,0.0) [-128.0|127.0] "" BMS
 SG_ Month : 16|8@1- (1.0,0.0) [-128.0|127.0] "" BMS
 SG_ Seconds : 48|8@1- (1.0,0.0) [-128.0|127.0] "" BMS
 SG_ Years : 0|16@1- (1.0,0.0) [-32768.0|32767.0] "" BMS
BA_DEF_ BO_ "GenMsgSendType" ENUM "cyclic";
BA_DEF_ SG_ "GenSigSendType" ENUM "cyclic";
BA_DEF_ BO_ "GenMsgCycleTime" INT 0 5000;
BA_ "GenMsgSendType" BO_ 1031 0;
BA_ "GenMsgCycleTime" BO_ 1031 500;
BA_ "GenSigSendType" SG_ 1031 BEMFd 0;
BA_ "GenSigSendType" SG_ 1031 BEMFq 0;
BA_ "GenMsgSendType" BO_ 57 0;
BA_ "GenMsgCycleTime" BO_ 57 5000;
BA_ "GenSigSendType" SG_ 57 BIM1BootloaderAddress 0;
BA_ "GenMsgSendType" BO_ 768 0;
BA_ "GenMsgCycleTime" BO_ 768 200;
BA_ "GenSigSendType" SG_ 768 BIM1MaxCellNumber 0;
BA_ "GenSigSendType" SG_ 768 BIM1MaxCellVoltage 0;
BA_ "GenSigSendType" SG_ 768 BIM1MinCellNumber 0;
BA_ "GenSigSendType" SG_ 768 BIM1MinCellVoltage 0;
BA_ "GenMsgSendType" BO_ 769 0;
BA_ "GenMsgCycleTime" BO_ 769 200;
BA_ "GenSigSendType" SG_ 769 BIM1AvgCellVoltage 0;
BA_ "GenSigSendType" SG_ 769 BIM1NumberBalancingCells 0;
BA_ "GenSigSendType" SG_ 769 BIM1StdevCellVoltage 0;
BA_ "GenMsgSendType" BO_ 176 0;
BA_ "GenMsgCycleTime" BO_ 176 5000;
BA_ "GenSigSendType" SG_ 176 BIM1CommandCode 0;
BA_ "GenSigSendType" SG_ 176 BIM1CommandValue 0;
BA_ "GenMsgSendType" BO_ 58 0;
BA_ "GenMsgCycleTime" BO_ 58 200;
BA_ "GenSigSendType" SG_ 58 BIM1BQ 0;
BA_ "GenSigSendType" SG_ 58 BIM1Init 0;
BA_ "GenSigSendType" SG_ 58 BIM1SPI 0;
BA_ "GenMsgSendType" BO_ 59 0;
BA_ "GenMsgCycleTime" BO_ 59 5000;
BA_ "GenSigSendType" SG_ 59 BIM2BootloaderAddres 0;
BA_ "GenMsgSendType" BO_ 770 0;
BA_ "GenMsgCycleTime" BO_ 770 250;
BA_ "GenSigSendType" SG_ 770 BIM2MaxCellNumber 0;
BA_ "GenSigSendType" SG_ 770 BIM2MaxCellVoltage 0;
BA_ "GenSigSendType" SG_ 770 BIM2MinCellNumber 0;
BA_ "GenSigSendType" SG_ 770 BIM2MinCellVoltage 0;
BA_ "GenMsgSendType" BO_ 771 0;
BA_ "GenMsgCycleTime" BO_ 771 250;
BA_ "GenSigSendType" SG_ 771 BIM2AvgCellVoltage 0;
BA_ "GenSigSendType" SG_ 771 BIM2NumberBalancingCells 0;
BA_ "GenSigSendType" SG_ 771 BIM2StdevCellVoltage 0;
BA_ "GenMsgSendType" BO_ 177 0;
BA_ "GenMsgCycleTime" BO_ 177 5000;
BA_ "GenSigSendType" SG_ 177 BIM2CommandCode 0;
BA_ "GenSigSendType" SG_ 177 BIM2CommandValue 0;
BA_ "GenMsgSendType" BO_ 60 0;
BA_ "GenMsgCycleTime" BO_ 60 200;
BA_ "GenSigSendType" SG_ 60 BIM2BQ 0;
BA_ "GenSigSendType" SG_ 60 BIM2Init 0;
BA_ "GenSigSendType" SG_ 60 BIM2SPI 0;
BA_ "GenMsgSendType" BO_ 61 0;
BA_ "GenMsgCycleTime" BO_ 61 5000;
BA_ "GenSigSendType" SG_ 61 BIM3BootloaderAddress 0;
BA_ "GenMsgSendType" BO_ 772 0;
BA_ "GenMsgCycleTime" BO_ 772 250;
BA_ "GenSigSendType" SG_ 772 BIM3MaxCellNumber 0;
BA_ "GenSigSendType" SG_ 772 BIM3MaxCellVoltage 0;
BA_ "GenSigSendType" SG_ 772 BIM3MinCellNumber 0;
BA_ "GenSigSendType" SG_ 772 BIM3MinCellVoltage 0;
BA_ "GenMsgSendType" BO_ 773 0;
BA_ "GenMsgCycleTime" BO_ 773 250;
BA_ "GenSigSendType" SG_ 773 BIM3AvgCellVoltage 0;
BA_ "GenSigSendType" SG_ 773 BIM3NumberBalancingCells 0;
BA_ "GenSigSendType" SG_ 773 BIM3StdevCellVoltage 0;
BA_ "GenMsgSendType" BO_ 178 0;
BA_ "GenMsgCycleTime" BO_ 178 5000;
BA_ "GenSigSendType" SG_ 178 BIM3CommandCode 0;
BA_ "GenSigSendType" SG_ 178 BIM3CommandValue 0;
BA_ "GenMsgSendType" BO_ 62 0;
BA_ "GenMsgCycleTime" BO_ 62 200;
BA_ "GenSigSendType" SG_ 62 BIM3BQ 0;
BA_ "GenSigSendType" SG_ 62 BIM3Init 0;
BA_ "GenSigSendType" SG_ 62 BIM3SPI 0;
BA_ "GenMsgSendType" BO_ 63 0;
BA_ "GenMsgCycleTime" BO_ 63 5000;
BA_ "GenSigSendType" SG_ 63 BIM4BootloaderAddres 0;
BA_ "GenMsgSendType" BO_ 774 0;
BA_ "GenMsgCycleTime" BO_ 774 250;
BA_ "GenSigSendType" SG_ 774 BIM4MaxCellNumber 0;
BA_ "GenSigSendType" SG_ 774 BIM4MaxCellVoltage 0;
BA_ "GenSigSendType" SG_ 774 BIM4MinCellNumber 0;
BA_ "GenSigSendType" SG_ 774 BIM4MinCellVoltage 0;
BA_ "GenMsgSendType" BO_ 775 0;
BA_ "GenMsgCycleTime" BO_ 775 250;
BA_ "GenSigSendType" SG_ 775 BIM4AvgCellVoltage 0;
BA_ "GenSigSendType" SG_ 775 BIM4NumberBalancingCells 0;
BA_ "GenSigSendType" SG_ 775 BIM4StdevCellVoltage 0;
BA_ "GenMsgSendType" BO_ 179 0;
BA_ "GenMsgCycleTime" BO_ 179 5000;
BA_ "GenSigSendType" SG_ 179 BIM4CommandCode 0;
BA_ "GenSigSendType" SG_ 179 BIM4CommandValue 0;
BA_ "GenMsgSendType" BO_ 64 0;
BA_ "GenMsgCycleTime" BO_ 64 200;
BA_ "GenSigSendType" SG_ 64 BIM4BQ 0;
BA_ "GenSigSendType" SG_ 64 BIM4Init 0;
BA_ "GenSigSendType" SG_ 64 BIM4SPI 0;
BA_ "GenMsgSendType" BO_ 1026 0;
BA_ "GenMsgCycleTime" BO_ 1026 500;
BA_ "GenSigSendType" SG_ 1026 BusCurrent 0;
BA_ "GenSigSendType" SG_ 1026 BusVoltage 0;
BA_ "GenMsgSendType" BO_ 262 0;
BA_ "GenMsgCycleTime" BO_ 262 200;
BA_ "GenSigSendType" SG_ 262 BusVoltage12V 0;
BA_ "GenMsgSendType" BO_ 170 0;
BA_ "GenMsgCycleTime" BO_ 170 5000;
BA_ "GenSigSendType" SG_ 170 CANcorderHeartbeat 0;
BA_ "GenMsgSendType" BO_ 48 0;
BA_ "GenMsgCycleTime" BO_ 48 5000;
BA_ "GenSigSendType" SG_ 48 CANMirrorBootloaderAddress 0;
BA_ "GenMsgSendType" BO_ 50 0;
BA_ "GenMsgCycleTime" BO_ 50 5000;
BA_ "GenSigSendType" SG_ 50 CANMirrorCommandCode 0;
BA_ "GenSigSendType" SG_ 50 CANMirrorCommandValue 0;
BA_ "GenMsgSendType" BO_ 49 0;
BA_ "GenMsgCycleTime" BO_ 49 200;
BA_ "GenSigSendType" SG_ 49 CANMirrorOverflowCounter 0;
BA_ "GenSigSendType" SG_ 49 Mirror_can_error 0;
BA_ "GenSigSendType" SG_ 49 Mirror_CANa_Status 0;
BA_ "GenSigSendType" SG_ 49 Timeout 0;
BA_ "GenMsgSendType" BO_ 810 0;
BA_ "GenMsgCycleTime" BO_ 810 500;
BA_ "GenSigSendType" SG_ 810 Cell103 0;
BA_ "GenSigSendType" SG_ 810 Cell103_bal 0;
BA_ "GenSigSendType" SG_ 810 Cell104 0;
BA_ "GenSigSendType" SG_ 810 Cell104_bal 0;
BA_ "GenSigSendType" SG_ 810 Cell105 0;
BA_ "GenSigSendType" SG_ 810 Cell105_bal 0;
BA_ "GenSigSendType" SG_ 810 Cell106 0;
BA_ "GenSigSendType" SG_ 810 Cell106_bal 0;
BA_ "GenMsgSendType" BO_ 811 0;
BA_ "GenMsgCycleTime" BO_ 811 500;
BA_ "GenSigSendType" SG_ 811 Cell107 0;
BA_ "GenSigSendType" SG_ 811 Cell107_bal 0;
BA_ "GenSigSendType" SG_ 811 Cell108 0;
BA_ "GenSigSendType" SG_ 811 Cell108_bal 0;
BA_ "GenSigSendType" SG_ 811 Cell109 0;
BA_ "GenSigSendType" SG_ 811 Cell109_bal 0;
BA_ "GenSigSendType" SG_ 811 Cell110 0;
BA_ "GenSigSendType" SG_ 811 Cell110_bal 0;
BA_ "GenMsgSendType" BO_ 787 0;
BA_ "GenMsgCycleTime" BO_ 787 250;
BA_ "GenSigSendType" SG_ 787 Cell13 0;
BA_ "GenSigSendType" SG_ 787 Cell13_bal 0;
BA_ "GenSigSendType" SG_ 787 Cell14 0;
BA_ "GenSigSendType" SG_ 787 Cell14_bal 0;
BA_ "GenSigSendType" SG_ 787 Cell15 0;
BA_ "GenSigSendType" SG_ 787 Cell15_bal 0;
BA_ "GenSigSendType" SG_ 787 Cell16 0;
BA_ "GenSigSendType" SG_ 787 Cell16_bal 0;
BA_ "GenMsgSendType" BO_ 788 0;
BA_ "GenMsgCycleTime" BO_ 788 250;
BA_ "GenSigSendType" SG_ 788 Cell17 0;
BA_ "GenSigSendType" SG_ 788 Cell17_bal 0;
BA_ "GenSigSendType" SG_ 788 Cell18 0;
BA_ "GenSigSendType" SG_ 788 Cell18_bal 0;
BA_ "GenSigSendType" SG_ 788 Cell19 0;
BA_ "GenSigSendType" SG_ 788 Cell19_bal 0;
BA_ "GenSigSendType" SG_ 788 Cell20 0;
BA_ "GenSigSendType" SG_ 788 Cell20_bal 0;
BA_ "GenMsgSendType" BO_ 784 0;
BA_ "GenMsgCycleTime" BO_ 784 250;
BA_ "GenSigSendType" SG_ 784 Cell1 0;
BA_ "GenSigSendType" SG_ 784 Cell1_bal 0;
BA_ "GenSigSendType" SG_ 784 Cell2 0;
BA_ "GenSigSendType" SG_ 784 Cell2_bal 0;
BA_ "GenSigSendType" SG_ 784 Cell3 0;
BA_ "GenSigSendType" SG_ 784 Cell3_bal 0;
BA_ "GenSigSendType" SG_ 784 Cell4 0;
BA_ "GenSigSendType" SG_ 784 Cell4_bal 0;
BA_ "GenMsgSendType" BO_ 789 0;
BA_ "GenMsgCycleTime" BO_ 789 250;
BA_ "GenSigSendType" SG_ 789 Cell21 0;
BA_ "GenSigSendType" SG_ 789 Cell21_bal 0;
BA_ "GenSigSendType" SG_ 789 Cell22 0;
BA_ "GenSigSendType" SG_ 789 Cell22_bal 0;
BA_ "GenSigSendType" SG_ 789 Cell23 0;
BA_ "GenSigSendType" SG_ 789 Cell23_bal 0;
BA_ "GenSigSendType" SG_ 789 Cell24 0;
BA_ "GenSigSendType" SG_ 789 Cell24_bal 0;
BA_ "GenMsgSendType" BO_ 790 0;
BA_ "GenMsgCycleTime" BO_ 790 250;
BA_ "GenSigSendType" SG_ 790 Cell25 0;
BA_ "GenSigSendType" SG_ 790 Cell25_bal 0;
BA_ "GenSigSendType" SG_ 790 Cell26 0;
BA_ "GenSigSendType" SG_ 790 Cell26_bal 0;
BA_ "GenSigSendType" SG_ 790 Cell27 0;
BA_ "GenSigSendType" SG_ 790 Cell27_bal 0;
BA_ "GenSigSendType" SG_ 790 Cell28 0;
BA_ "GenSigSendType" SG_ 790 Cell28_bal 0;
BA_ "GenMsgSendType" BO_ 791 0;
BA_ "GenMsgCycleTime" BO_ 791 250;
BA_ "GenSigSendType" SG_ 791 Cell29 0;
BA_ "GenSigSendType" SG_ 791 Cell29_bal 0;
BA_ "GenSigSendType" SG_ 791 Cell30 0;
BA_ "GenSigSendType" SG_ 791 Cell30_bal 0;
BA_ "GenSigSendType" SG_ 791 Cell31 0;
BA_ "GenSigSendType" SG_ 791 Cell31_bal 0;
BA_ "GenSigSendType" SG_ 791 Cell32 0;
BA_ "GenSigSendType" SG_ 791 Cell32_bal 0;
BA_ "GenMsgSendType" BO_ 792 0;
BA_ "GenMsgCycleTime" BO_ 792 250;
BA_ "GenSigSendType" SG_ 792 Cell33 0;
BA_ "GenSigSendType" SG_ 792 Cell33_bal 0;
BA_ "GenSigSendType" SG_ 792 Cell34 0;
BA_ "GenSigSendType" SG_ 792 Cell34_bal 0;
BA_ "GenSigSendType" SG_ 792 Cell35 0;
BA_ "GenSigSendType" SG_ 792 Cell35_bal 0;
BA_ "GenSigSendType" SG_ 792 Cell36 0;
BA_ "GenSigSendType" SG_ 792 Cell36_bal 0;
BA_ "GenMsgSendType" BO_ 793 0;
BA_ "GenMsgCycleTime" BO_ 793 250;
BA_ "GenSigSendType" SG_ 793 Cell37 0;
BA_ "GenSigSendType" SG_ 793 Cell37_bal 0;
BA_ "GenSigSendType" SG_ 793 Cell38 0;
BA_ "GenSigSendType" SG_ 793 Cell38_bal 0;
BA_ "GenSigSendType" SG_ 793 Cell39 0;
BA_ "GenSigSendType" SG_ 793 Cell39_bal 0;
BA_ "GenSigSendType" SG_ 793 Cell40 0;
BA_ "GenSigSendType" SG_ 793 Cell40_bal 0;
BA_ "GenMsgSendType" BO_ 794 0;
BA_ "GenMsgCycleTime" BO_ 794 250;
BA_ "GenSigSendType" SG_ 794 Cell41 0;
BA_ "GenSigSendType" SG_ 794 Cell41_bal 0;
BA_ "GenSigSendType" SG_ 794 Cell42 0;
BA_ "GenSigSendType" SG_ 794 Cell42_bal 0;
BA_ "GenSigSendType" SG_ 794 Cell43 0;
BA_ "GenSigSendType" SG_ 794 Cell43_bal 0;
BA_ "GenSigSendType" SG_ 794 Cell44 0;
BA_ "GenSigSendType" SG_ 794 Cell44_bal 0;
BA_ "GenMsgSendType" BO_ 795 0;
BA_ "GenMsgCycleTime" BO_ 795 250;
BA_ "GenSigSendType" SG_ 795 Cell45 0;
BA_ "GenSigSendType" SG_ 795 Cell45_bal 0;
BA_ "GenSigSendType" SG_ 795 Cell46 0;
BA_ "GenSigSendType" SG_ 795 Cell46_bal 0;
BA_ "GenSigSendType" SG_ 795 Cell47 0;
BA_ "GenSigSendType" SG_ 795 Cell47_bal 0;
BA_ "GenSigSendType" SG_ 795 Cell48 0;
BA_ "GenSigSendType" SG_ 795 Cell48_bal 0;
BA_ "GenMsgSendType" BO_ 796 0;
BA_ "GenMsgCycleTime" BO_ 796 250;
BA_ "GenSigSendType" SG_ 796 Cell49 0;
BA_ "GenSigSendType" SG_ 796 Cell49_bal 0;
BA_ "GenSigSendType" SG_ 796 Cell50 0;
BA_ "GenSigSendType" SG_ 796 Cell50_bal 0;
BA_ "GenSigSendType" SG_ 796 Cell51 0;
BA_ "GenSigSendType" SG_ 796 Cell51_bal 0;
BA_ "GenSigSendType" SG_ 796 Cell52 0;
BA_ "GenSigSendType" SG_ 796 Cell52_bal 0;
BA_ "GenMsgSendType" BO_ 797 0;
BA_ "GenMsgCycleTime" BO_ 797 250;
BA_ "GenSigSendType" SG_ 797 Cell53 0;
BA_ "GenSigSendType" SG_ 797 Cell53_bal 0;
BA_ "GenSigSendType" SG_ 797 Cell54 0;
BA_ "GenSigSendType" SG_ 797 Cell54_bal 0;
BA_ "GenMsgSendType" BO_ 798 0;
BA_ "GenMsgCycleTime" BO_ 798 250;
BA_ "GenSigSendType" SG_ 798 Cell55 0;
BA_ "GenSigSendType" SG_ 798 Cell55_bal 0;
BA_ "GenSigSendType" SG_ 798 Cell56 0;
BA_ "GenSigSendType" SG_ 798 Cell56_bal 0;
BA_ "GenSigSendType" SG_ 798 Cell57 0;
BA_ "GenSigSendType" SG_ 798 Cell57_bal 0;
BA_ "GenSigSendType" SG_ 798 Cell58 0;
BA_ "GenSigSendType" SG_ 798 Cell58_bal 0;
BA_ "GenMsgSendType" BO_ 799 0;
BA_ "GenMsgCycleTime" BO_ 799 250;
BA_ "GenSigSendType" SG_ 799 Cell59 0;
BA_ "GenSigSendType" SG_ 799 Cell59_bal 0;
BA_ "GenSigSendType" SG_ 799 Cell60 0;
BA_ "GenSigSendType" SG_ 799 Cell60_bal 0;
BA_ "GenSigSendType" SG_ 799 Cell61 0;
BA_ "GenSigSendType" SG_ 799 Cell61_bal 0;
BA_ "GenSigSendType" SG_ 799 Cell62 0;
BA_ "GenSigSendType" SG_ 799 Cell62_bal 0;
BA_ "GenMsgSendType" BO_ 785 0;
BA_ "GenMsgCycleTime" BO_ 785 250;
BA_ "GenSigSendType" SG_ 785 Cell5 0;
BA_ "GenSigSendType" SG_ 785 Cell5_bal 0;
BA_ "GenSigSendType" SG_ 785 Cell6 0;
BA_ "GenSigSendType" SG_ 785 Cell6_bal 0;
BA_ "GenSigSendType" SG_ 785 Cell7 0;
BA_ "GenSigSendType" SG_ 785 Cell7_bal 0;
BA_ "GenSigSendType" SG_ 785 Cell8 0;
BA_ "GenSigSendType" SG_ 785 Cell8_bal 0;
BA_ "GenMsgSendType" BO_ 800 0;
BA_ "GenMsgCycleTime" BO_ 800 500;
BA_ "GenSigSendType" SG_ 800 Cell63 0;
BA_ "GenSigSendType" SG_ 800 Cell63_bal 0;
BA_ "GenSigSendType" SG_ 800 Cell64 0;
BA_ "GenSigSendType" SG_ 800 Cell64_bal 0;
BA_ "GenSigSendType" SG_ 800 Cell65 0;
BA_ "GenSigSendType" SG_ 800 Cell65_bal 0;
BA_ "GenSigSendType" SG_ 800 Cell66 0;
BA_ "GenSigSendType" SG_ 800 Cell66_bal 0;
BA_ "GenMsgSendType" BO_ 801 0;
BA_ "GenMsgCycleTime" BO_ 801 500;
BA_ "GenSigSendType" SG_ 801 Cell67 0;
BA_ "GenSigSendType" SG_ 801 Cell67_bal 0;
BA_ "GenSigSendType" SG_ 801 Cell68 0;
BA_ "GenSigSendType" SG_ 801 Cell68_bal 0;
BA_ "GenSigSendType" SG_ 801 Cell69 0;
BA_ "GenSigSendType" SG_ 801 Cell69_bal 0;
BA_ "GenSigSendType" SG_ 801 Cell70 0;
BA_ "GenSigSendType" SG_ 801 Cell70_bal 0;
BA_ "GenMsgSendType" BO_ 802 0;
BA_ "GenMsgCycleTime" BO_ 802 500;
BA_ "GenSigSendType" SG_ 802 Cell71 0;
BA_ "GenSigSendType" SG_ 802 Cell71_bal 0;
BA_ "GenSigSendType" SG_ 802 Cell72 0;
BA_ "GenSigSendType" SG_ 802 Cell72_bal 0;
BA_ "GenSigSendType" SG_ 802 Cell73 0;
BA_ "GenSigSendType" SG_ 802 Cell73_bal 0;
BA_ "GenSigSendType" SG_ 802 Cell74 0;
BA_ "GenSigSendType" SG_ 802 Cell74_bal 0;
BA_ "GenMsgSendType" BO_ 803 0;
BA_ "GenMsgCycleTime" BO_ 803 500;
BA_ "GenSigSendType" SG_ 803 Cell75 0;
BA_ "GenSigSendType" SG_ 803 Cell75_bal 0;
BA_ "GenSigSendType" SG_ 803 Cell76 0;
BA_ "GenSigSendType" SG_ 803 Cell76_bal 0;
BA_ "GenSigSendType" SG_ 803 Cell77 0;
BA_ "GenSigSendType" SG_ 803 Cell77_bal 0;
BA_ "GenSigSendType" SG_ 803 Cell78 0;
BA_ "GenSigSendType" SG_ 803 Cell78_bal 0;
BA_ "GenMsgSendType" BO_ 804 0;
BA_ "GenMsgCycleTime" BO_ 804 500;
BA_ "GenSigSendType" SG_ 804 Cell79 0;
BA_ "GenSigSendType" SG_ 804 Cell79_bal 0;
BA_ "GenSigSendType" SG_ 804 Cell80 0;
BA_ "GenSigSendType" SG_ 804 Cell80_bal 0;
BA_ "GenSigSendType" SG_ 804 Cell81 0;
BA_ "GenSigSendType" SG_ 804 Cell81_bal 0;
BA_ "GenSigSendType" SG_ 804 Cell82 0;
BA_ "GenSigSendType" SG_ 804 Cell82_bal 0;
BA_ "GenMsgSendType" BO_ 805 0;
BA_ "GenMsgCycleTime" BO_ 805 500;
BA_ "GenSigSendType" SG_ 805 Cell83 0;
BA_ "GenSigSendType" SG_ 805 Cell83_bal 0;
BA_ "GenSigSendType" SG_ 805 Cell84 0;
BA_ "GenSigSendType" SG_ 805 Cell84_bal 0;
BA_ "GenSigSendType" SG_ 805 Cell85 0;
BA_ "GenSigSendType" SG_ 805 Cell85_bal 0;
BA_ "GenSigSendType" SG_ 805 Cell86 0;
BA_ "GenSigSendType" SG_ 805 Cell86_bal 0;
BA_ "GenMsgSendType" BO_ 806 0;
BA_ "GenMsgCycleTime" BO_ 806 500;
BA_ "GenSigSendType" SG_ 806 Cell87 0;
BA_ "GenSigSendType" SG_ 806 Cell87_bal 0;
BA_ "GenSigSendType" SG_ 806 Cell88 0;
BA_ "GenSigSendType" SG_ 806 Cell88_bal 0;
BA_ "GenSigSendType" SG_ 806 Cell89 0;
BA_ "GenSigSendType" SG_ 806 Cell89_bal 0;
BA_ "GenSigSendType" SG_ 806 Cell90 0;
BA_ "GenSigSendType" SG_ 806 Cell90_bal 0;
BA_ "GenMsgSendType" BO_ 807 0;
BA_ "GenMsgCycleTime" BO_ 807 500;
BA_ "GenSigSendType" SG_ 807 Cell91 0;
BA_ "GenSigSendType" SG_ 807 Cell91_bal 0;
BA_ "GenSigSendType" SG_ 807 Cell92 0;
BA_ "GenSigSendType" SG_ 807 Cell92_bal 0;
BA_ "GenSigSendType" SG_ 807 Cell93 0;
BA_ "GenSigSendType" SG_ 807 Cell93_bal 0;
BA_ "GenSigSendType" SG_ 807 Cell94 0;
BA_ "GenSigSendType" SG_ 807 Cell94_bal 0;
BA_ "GenMsgSendType" BO_ 808 0;
BA_ "GenMsgCycleTime" BO_ 808 500;
BA_ "GenSigSendType" SG_ 808 Cell95 0;
BA_ "GenSigSendType" SG_ 808 Cell95_bal 0;
BA_ "GenSigSendType" SG_ 808 Cell96 0;
BA_ "GenSigSendType" SG_ 808 Cell96_bal 0;
BA_ "GenSigSendType" SG_ 808 Cell97 0;
BA_ "GenSigSendType" SG_ 808 Cell97_bal 0;
BA_ "GenSigSendType" SG_ 808 Cell98 0;
BA_ "GenSigSendType" SG_ 808 Cell98_bal 0;
BA_ "GenMsgSendType" BO_ 809 0;
BA_ "GenMsgCycleTime" BO_ 809 500;
BA_ "GenSigSendType" SG_ 809 Cell100 0;
BA_ "GenSigSendType" SG_ 809 Cell100_bal 0;
BA_ "GenSigSendType" SG_ 809 Cell101 0;
BA_ "GenSigSendType" SG_ 809 Cell101_bal 0;
BA_ "GenSigSendType" SG_ 809 Cell102 0;
BA_ "GenSigSendType" SG_ 809 Cell102_bal 0;
BA_ "GenSigSendType" SG_ 809 Cell99 0;
BA_ "GenSigSendType" SG_ 809 Cell99_bal 0;
BA_ "GenMsgSendType" BO_ 786 0;
BA_ "GenMsgCycleTime" BO_ 786 250;
BA_ "GenSigSendType" SG_ 786 Cell10 0;
BA_ "GenSigSendType" SG_ 786 Cell10_bal 0;
BA_ "GenSigSendType" SG_ 786 Cell11 0;
BA_ "GenSigSendType" SG_ 786 Cell11_bal 0;
BA_ "GenSigSendType" SG_ 786 Cell12 0;
BA_ "GenSigSendType" SG_ 786 Cell12_bal 0;
BA_ "GenSigSendType" SG_ 786 Cell9 0;
BA_ "GenSigSendType" SG_ 786 Cell9_bal 0;
BA_ "GenMsgSendType" BO_ 270 0;
BA_ "GenMsgCycleTime" BO_ 270 200;
BA_ "GenSigSendType" SG_ 270 Day 0;
BA_ "GenSigSendType" SG_ 270 Hours 0;
BA_ "GenSigSendType" SG_ 270 Minutes 0;
BA_ "GenSigSendType" SG_ 270 Month 0;
BA_ "GenSigSendType" SG_ 270 Seconds 0;
BA_ "GenSigSendType" SG_ 270 Years 0;
